# RK3399-M0 register map
File version: 1
CPU: CM0 r0p1, little endian, no MPU, no FPU, 4 interrupt priority bits, 32 interrupts
Registers are 32-bit, read-write, reset 0x0 unless marked. A register's access mark holds for its fields unless they carry their own. Offsets are from the block's base; [hi:lo] are bit positions; {n}, {i} and the like mark numbered series; 'fields as' and 'values as' point back to an identical list.

## MAILBOX1
Base 0x47390000
Same registers: MAILBOX0 0x476B0000
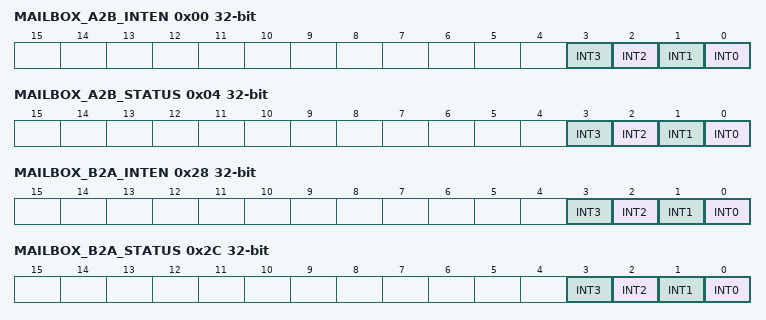
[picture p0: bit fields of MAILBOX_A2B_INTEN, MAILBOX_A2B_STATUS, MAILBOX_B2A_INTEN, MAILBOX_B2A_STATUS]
0x00 MAILBOX_A2B_INTEN — Cortex-A53/Cortex-A72 to Cortex-M0 interrupt enable register/Cortex-A53/Cortex-A72 to MCU interrupt enable register
  [n] INT{n} (n=0..3) — interrupt enable for int{n}
0x04 MAILBOX_A2B_STATUS — Cortex-A53/Cortex-A72 to Cortex-M0 interrupt status register/Cortex-A53/Cortex-A72 to MCU interrupt status register
  [n] INT{n} (n=0..3) — interrupt status for int{n}. when writte 1, int is cleared.
{0x8+8i} MAILBOX_A2B_CMD_{i} (i=0..3) — Cortex-A53/Cortex-A72 to Cortex-M0 command {i}/Cortex-A53/Cortex-A72 to MCU command {i}
  [31:0] COMMAND — command of Cortex-A53/Cortex-A72 to Cortex-M0
{0xC+8i} MAILBOX_A2B_DAT_{i} (i=0..3) — Cortex-A53/Cortex-A72 to Cortex-M0 data {i}/Cortex-A53/Cortex-A72 to MCU data {i}
  [31:0] DATA — data of Cortex-A53/Cortex-A72 to Cortex-M0
0x28 MAILBOX_B2A_INTEN — Cortex-A53/Cortex-A72 to Cortex-M0 interrupt enable register/Cortex-A53/Cortex-A72 to MCU interrupt enable register
  [n] INT{n} (n=0..3) — interrupt enable for int{n}
0x2C MAILBOX_B2A_STATUS — Cortex-M0 to Cortex-A53/Cortex-A72 interrupt status register/MCU to Cortex-A53/Cortex-A72 interrupt status register
  fields as MAILBOX_A2B_STATUS
0x30 MAILBOX_B2A_CMD_0 — Cortex-M0 to Cortex-A53/Cortex-A72 command 0/MCU to Cortex-A53/Cortex-A72 command 0
  [31:0] COMMAND — command of MCU to Cortex-A53/Cortex-A72
0x34 MAILBOX_B2A_DAT_0 — Cortex-M0 to Cortex-A53/Cortex-A72 data 0/MCU to Cortex-A53/Cortex-A72 data 0
  [31:0] DATA — data of MCU to Cortex-A53/Cortex-A72
0x38 MAILBOX_B2A_CMD_1 — Cortex-M0 to Cortex-A53/Cortex-A72 command 1/MCU to Cortex-A53/Cortex-A72 command 1
  [31:0] COMMAND — command of MCU to Cortex-A53/Cortex-A72
0x3C MAILBOX_B2A_DAT_1 — Cortex-M0 to Cortex-A53/Cortex-A72 data 1/MCU to Cortex-A53/Cortex-A72 data 1
  [31:0] DATA — data of MCU to Cortex-A53/Cortex-A72
0x40 MAILBOX_B2A_CMD_2 — Cortex-M0 to Cortex-A53/Cortex-A72 command 2/MCU to Cortex-A53/Cortex-A72 command 2
  [31:0] COMMAND — command of Cortex-M0 to Cortex-A53/Cortex-A72
0x44 MAILBOX_B2A_DAT_2 — Cortex-M0 to Cortex-A53/Cortex-A72 data 2/MCU to Cortex-A53/Cortex-A72 data 2
  [31:0] DATA — data of Cortex-M0 to Cortex-A53/Cortex-A72
0x48 MAILBOX_B2A_CMD_3 — Cortex-M0 to Cortex-A53/Cortex-A72 command 3/MCU to Cortex-A53/Cortex-A72 command 3
  [31:0] COMMAND — command of Cortex-M0 to Cortex-A53/Cortex-A72
0x4C MAILBOX_B2A_DAT_3 — Cortex-M0 to Cortex-A53/Cortex-A72 data 3/MCU to Cortex-A53/Cortex-A72 data 3
  [31:0] DATA — data of Cortex-M0 to Cortex-A53/Cortex-A72
{0x100+4i} MAILBOX_ATOMIC_LOCK_{i:02} (i=0..31) — Lock flag register {i:02}
  [0] ATOMIC_LOCK_{i:02} — lock flag bit {i:02}

## TIMER0
Base 0x47850000
Same registers: PMUTIMER0 0x47360000, PMUTIMER1 0x47360020, TIMER1 0x47850020, TIMER2 0x47850040, TIMER3 0x47850060, TIMER4 0x47850080, TIMER5 0x47850100, TIMER6 0x47858000, TIMER7 0x47858020, TIMER8 0x47858040, TIMER9 0x47858060, TIMER10 0x47858080, TIMER11 0x47858100, STIMER0 0x47860000, STIMER1 0x47860020, STIMER2 0x47860040, STIMER3 0x47860060, STIMER4 0x47860080, STIMER5 0x47860100, STIMER6 0x47868000, STIMER7 0x47868020, STIMER8 0x47868040, STIMER9 0x47868060, STIMER10 0x47868080, STIMER11 0x47868100
0x00 TIMER_n_LOAD_COUNT0 access not given — Timer n higher Load Count Register
0x04 TIMER_n_LOAD_COUNT1 access not given — Timer n higher Load Count Register
0x08 TIMER_n_CURRENT_VALUE0 access not given — Timer n Current Value Register
0x0C TIMER_n_CURRENT_VALUE1 access not given — Timer n Current Value Register
0x10 TIMER_n_LOAD_COUNT2 access not given — Timer n lower Load Count Register
0x14 TIMER_n_LOAD_COUNT3 access not given — Timer n lower Load Count Register
0x18 TIMER_n_INTSTATUS access not given — Timer Interrupt Stauts Register
0x1C TIMER_n_CONTROLREG access not given — Timer n Control Register
